# UPD70F3508 register map
Vendor: Renesas; Series: V850E2/Px4; File version: 1.0
CPU: other r0p0, little endian, no MPU, FPU, 4 interrupt priority bits
Registers are 8-bit, read-write, reset 0x0 unless marked. A register's access mark holds for its fields unless they carry their own. Offsets are from the block's base; [hi:lo] are bit positions.

## CSIH1_B1 — Queue-Equipped Three-Line Serial Interface H 1, Bank 1 (memory/Tx/Rx/status registers at base1)
Base 0xFFFFE100
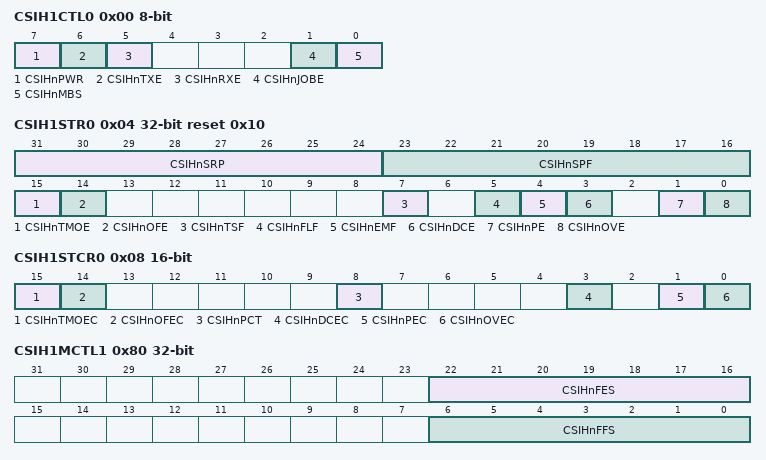
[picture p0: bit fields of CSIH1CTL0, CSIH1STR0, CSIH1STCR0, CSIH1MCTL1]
0x00 CSIH1CTL0 — CSIH1 Control Register 0 — operation clock, Tx/Rx enable, memory bypass
  [7] CSIHnPWR — Operation clock control
  [6] CSIHnTXE — Transmission enable
  [5] CSIHnRXE — Reception enable
  [1] CSIHnJOBE — Job abort at end of current job
  [0] CSIHnMBS — Memory bypass (0=memory mode, 1=direct access)
0x04 CSIH1STR0 32-bit ro reset 0x10 — CSIH1 Status Register 0 — FIFO pointers, error flags, transfer status
  [31:24] CSIHnSRP — Received words in FIFO [7:0]
  [23:16] CSIHnSPF — Untransmitted data count in FIFO [7:0]
  [15] CSIHnTMOE — Time-out error flag
  [14] CSIHnOFE — Overflow error flag
  [7] CSIHnTSF — Transfer status flag
  [5] CSIHnFLF — FIFO full flag
  [4] CSIHnEMF — FIFO empty flag
  [3] CSIHnDCE — Data consistency check error flag
  [1] CSIHnPE — Parity error flag
  [0] CSIHnOVE — Overrun error flag
0x08 CSIH1STCR0 16-bit wo — CSIH1 Status Clear Register 0 — clears STR0 flags; always reads 0x0000
  [15] CSIHnTMOEC — Clear time-out error flag
  [14] CSIHnOFEC — Clear overflow error flag
  [8] CSIHnPCT — FIFO pointer clear command
  [3] CSIHnDCEC — Clear data consistency error flag
  [1] CSIHnPEC — Clear parity error flag
  [0] CSIHnOVEC — Clear overrun error flag
0x80 CSIH1MCTL1 32-bit — CSIH1 Memory Control Register 1 — FIFO interrupt threshold levels
  [22:16] CSIHnFES — Tx FIFO empty interrupt threshold [6:0]
  [6:0] CSIHnFFS — Rx FIFO full interrupt threshold [6:0]
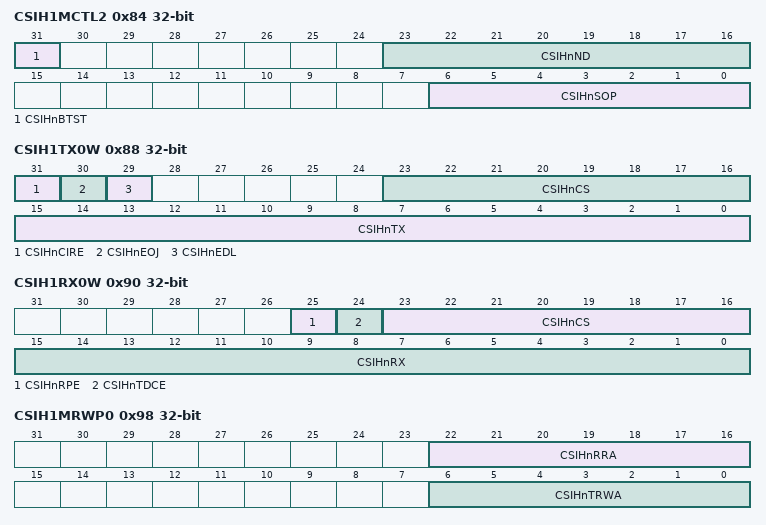
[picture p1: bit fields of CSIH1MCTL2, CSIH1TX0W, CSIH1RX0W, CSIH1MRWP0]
0x84 CSIH1MCTL2 32-bit — CSIH1 Memory Control Register 2 — buffer transfer start, data count, send pointer
  [31] CSIHnBTST — Buffer transfer start trigger
  [23:16] CSIHnND — Number of data for buffer modes [7:0]
  [6:0] CSIHnSOP — Send pointer [6:0]
0x88 CSIH1TX0W 32-bit — CSIH1 Transmission Register 0 for Word Access
  [31] CSIHnCIRE — Communication interrupt request enable for this frame
  [30] CSIHnEOJ — End-of-job marker
  [29] CSIHnEDL — Extended data length for this frame
  [23:16] CSIHnCS — Chip-select activation bitmap [7:0] (bits 19:16 used for CSIH1 CS0-CS3)
  [15:0] CSIHnTX — Transmission data [15:0]
0x8C CSIH1TX0H 16-bit — CSIH1 Transmission Register 0 for Half Word Access — same as TX0W[15:0]
  [15:0] CSIHnTX — Transmission data [15:0]
0x90 CSIH1RX0W 32-bit ro — CSIH1 Reception Register 0 for Word Access
  [25] CSIHnRPE — Reception parity error on this frame
  [24] CSIHnTDCE — Transmission data consistency error on this frame
  [23:16] CSIHnCS — Chip-select active bitmap for this frame [7:0]
  [15:0] CSIHnRX — Received data [15:0]
0x94 CSIH1RX0H 16-bit ro — CSIH1 Reception Register 0 for Half Word Access — same as RX0W[15:0]
  [15:0] CSIHnRX — Received data [15:0]
0x98 CSIH1MRWP0 32-bit — CSIH1 Memory Read/Write Pointer Register 0 — Rx and Tx buffer pointers
  [22:16] CSIHnRRA — Rx buffer read pointer [6:0]
  [6:0] CSIHnTRWA — Tx buffer read/write pointer [6:0]

## CSIG0_B1 — Clocked Serial Interface G 0 - base1 region (CTL0, STR0, STCR0, BCTL0, TX0W, TX0H, RX0)
Base 0xFFFFE400
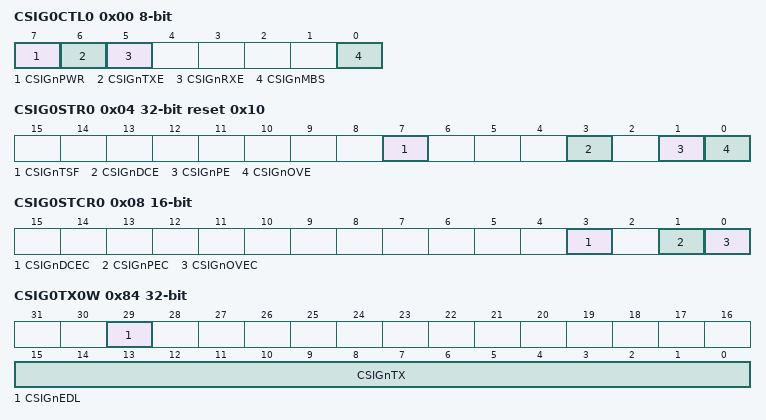
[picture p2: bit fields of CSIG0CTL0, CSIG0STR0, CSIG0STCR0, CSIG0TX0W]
0x00 CSIG0CTL0 — CSIG0 Control Register 0 - operation clock, TX/RX enable
  [7] CSIGnPWR — Operation clock: 0=stop, 1=provide
  [6] CSIGnTXE — Transmission enable: 0=disabled, 1=enabled
  [5] CSIGnRXE — Reception enable: 0=disabled, 1=enabled
  [0] CSIGnMBS — Must be set to 1 before activating CSIG
0x04 CSIG0STR0 32-bit ro reset 0x10 — CSIG0 Status Register 0
  [7] CSIGnTSF — Transfer status: 0=idle, 1=transfer in progress or pending
  [3] CSIGnDCE — Data consistency error flag: 0=none, 1=error detected
  [1] CSIGnPE — Parity error flag: 0=none, 1=parity error detected
  [0] CSIGnOVE — Overrun error flag: 0=none, 1=overrun detected
0x08 CSIG0STCR0 16-bit — CSIG0 Status Clear Register 0 - clears STR0 error flags
  [3] CSIGnDCEC — Clear DCE flag: write 1 to clear CSIGnSTR0.CSIGnDCE
  [1] CSIGnPEC — Clear PE flag: write 1 to clear CSIGnSTR0.CSIGnPE
  [0] CSIGnOVEC — Clear OVE flag: write 1 to clear CSIGnSTR0.CSIGnOVE
0x80 CSIG0BCTL0 reset 0x1 — CSIG0 Receive-Only Mode Control Register 0
  [0] CSIGnSCE — Next reception enable on RX0 read: 0=disabled, 1=enabled
0x84 CSIG0TX0W 32-bit — CSIG0 Transmission Register 0 - word access (use with EDL)
  [29] CSIGnEDL — Extended data length: 0=normal, 1=transmit as 16-bit EDL block
  [15:0] CSIGnTX — Transmit data [15:0]
0x88 CSIG0TX0H 16-bit — CSIG0 Transmission Register 0 - half-word access (use without EDL)
  [15:0] CSIGnTX — Transmit data [15:0]
0x8C CSIG0RX0 16-bit ro — CSIG0 Reception Register 0
  [15:0] CSIGnRX — Received data [15:0]
